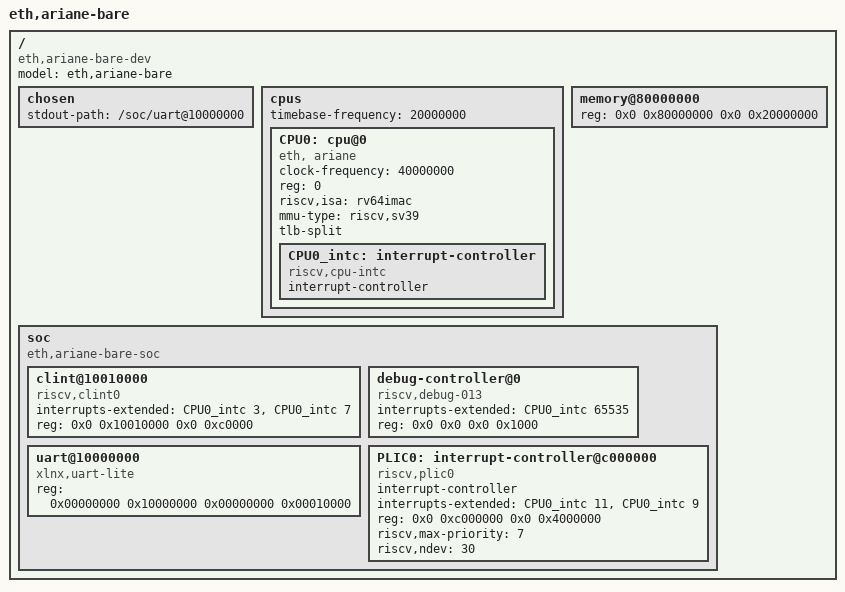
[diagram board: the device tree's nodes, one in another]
/* SPDX-License-Identifier: SHL-0.51 */

/* Copyright 2018 ETH Zurich and University of Bologna.
 * Copyright and related rights are licensed under the Solderpad Hardware
 * License, Version 0.51 (the "License"); you may not use this file except in
 * compliance with the License.  You may obtain a copy of the License at
 * http://solderpad.org/licenses/SHL-0.51. Unless required by applicable law
 * or agreed to in writing, software, hardware and materials distributed under
 * this License is distributed on an "AS IS" BASIS, WITHOUT WARRANTIES OR
 * CONDITIONS OF ANY KIND, either express or implied. See the License for the
 * specific language governing permissions and limitations under the License.
 */

/dts-v1/;

/ {
  #address-cells = <2>;
  #size-cells = <2>;
  compatible = "eth,ariane-bare-dev";
  model = "eth,ariane-bare";
  chosen {
    stdout-path = "/soc/uart@10000000";
  };
  cpus {
    #address-cells = <1>;
    #size-cells = <0>;
    timebase-frequency = <20000000>; // 20 MHz
    CPU0: cpu@0 {
      clock-frequency = <40000000>; // 40 MHz
      device_type = "cpu";
      reg = <0>;
      status = "okay";
      compatible = "eth, ariane", "riscv";
      riscv,isa = "rv64imac";
      mmu-type = "riscv,sv39";
      tlb-split;
      // HLIC - hart local interrupt controller
      CPU0_intc: interrupt-controller {
        #interrupt-cells = <1>;
        interrupt-controller;
        compatible = "riscv,cpu-intc";
      };
    };
  };
  memory@80000000 {
    device_type = "memory";
    reg = <0x0 0x80000000 0x0 0x20000000>;
  };
  soc {
    #address-cells = <2>;
    #size-cells = <2>;
    compatible = "eth,ariane-bare-soc", "simple-bus";
    ranges;
    clint@10010000 {
      compatible = "riscv,clint0";
      interrupts-extended = <&CPU0_intc 3 &CPU0_intc 7>;
      reg = <0x0 0x10010000 0x0 0xc0000>;
      reg-names = "control";
    };
    debug-controller@0 {
      compatible = "riscv,debug-013";
      interrupts-extended = <&CPU0_intc 65535>;
      reg = <0x0 0x0 0x0 0x1000>;
      reg-names = "control";
    };
    uart@10000000 {
      compatible = "xlnx,uart-lite";
      //interrupt-parent = <0x0000000b>;
      //interrupts = <0x00000004>;
      reg = <0x00000000 0x10000000 0x00000000 0x00010000>;
      reg-names = "control";
      //clocks = <0x00000016>;
    };
    PLIC0: interrupt-controller@c000000 {
      #address-cells = <0>;
      #interrupt-cells = <1>;
      compatible = "riscv,plic0";
      interrupt-controller;
      interrupts-extended = <&CPU0_intc 11 &CPU0_intc 9>;
      reg = <0x0 0xc000000 0x0 0x4000000>;
      riscv,max-priority = <7>;
      riscv,ndev = <30>;
    };
  };
};
